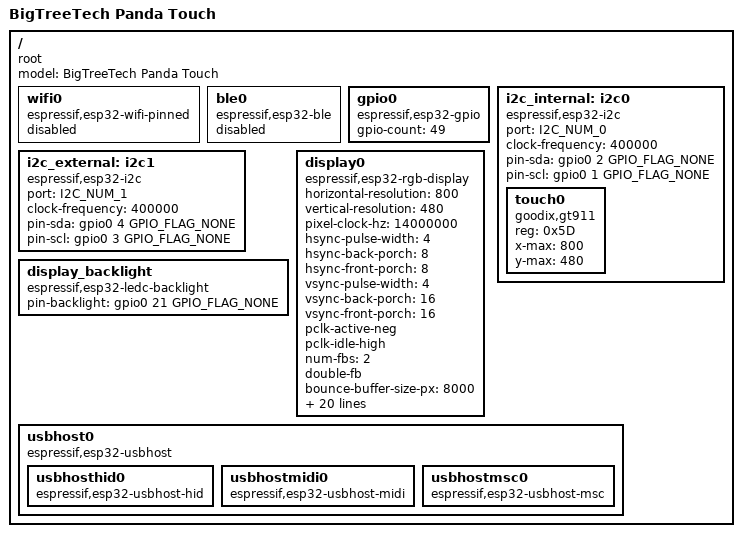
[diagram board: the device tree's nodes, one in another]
/dts-v1/;

#include <tactility/bindings/root.h>
#include <tactility/bindings/esp32_ble.h>
#include <tactility/bindings/esp32_wifi_pinned.h>
#include <tactility/bindings/esp32_gpio.h>
#include <tactility/bindings/esp32_i2c.h>
#include <tactility/bindings/esp32_usbhost.h>
#include <tactility/bindings/esp32_ledc_backlight.h>
#include <bindings/rgb_display.h>
#include <bindings/gt911.h>

// Reference: https://github.com/bigtreetech/PandaTouch_PlatformIO/blob/master/docs/PINOUT.md
/ {
	compatible = "root";
	model = "BigTreeTech Panda Touch";

	wifi0 {
		compatible = "espressif,esp32-wifi-pinned";
		status = "disabled";
	};

	ble0 {
		compatible = "espressif,esp32-ble";
		status = "disabled";
	};

	gpio0 {
		compatible = "espressif,esp32-gpio";
		gpio-count = <49>;
	};

	i2c_internal: i2c0 {
		compatible = "espressif,esp32-i2c";
		port = <I2C_NUM_0>;
		clock-frequency = <400000>;
		pin-sda = <&gpio0 2 GPIO_FLAG_NONE>;
		pin-scl = <&gpio0 1 GPIO_FLAG_NONE>;

		touch0 {
			// Reset pin 41 and interrupt pin 40 exist on the board but are not wired up here
			// (unverified - left disconnected like the original deprecated-HAL config).
			compatible = "goodix,gt911";
			reg = <0x5D>;
			x-max = <800>;
			y-max = <480>;
		};
	};

	i2c_external: i2c1 {
		compatible = "espressif,esp32-i2c";
		port = <I2C_NUM_1>;
		clock-frequency = <400000>;
		pin-sda = <&gpio0 4 GPIO_FLAG_NONE>;
		pin-scl = <&gpio0 3 GPIO_FLAG_NONE>;
	};

	display_backlight {
		compatible = "espressif,esp32-ledc-backlight";
		pin-backlight = <&gpio0 21 GPIO_FLAG_NONE>;
	};

	display0 {
		compatible = "espressif,esp32-rgb-display";
		horizontal-resolution = <800>;
		vertical-resolution = <480>;
		pixel-clock-hz = <14000000>;
		hsync-pulse-width = <4>;
		hsync-back-porch = <8>;
		hsync-front-porch = <8>;
		vsync-pulse-width = <4>;
		vsync-back-porch = <16>;
		vsync-front-porch = <16>;
		pclk-active-neg;
		pclk-idle-high;
		num-fbs = <2>;
		double-fb;
		bounce-buffer-size-px = <8000>;
		pin-de = <&gpio0 38 GPIO_FLAG_NONE>;
		pin-pclk = <&gpio0 5 GPIO_FLAG_NONE>;
		pin-reset = <&gpio0 46 GPIO_FLAG_NONE>;
		pin-data0 = <&gpio0 17 GPIO_FLAG_NONE>; // B
		pin-data1 = <&gpio0 18 GPIO_FLAG_NONE>; // B
		pin-data2 = <&gpio0 48 GPIO_FLAG_NONE>; // B
		pin-data3 = <&gpio0 47 GPIO_FLAG_NONE>; // B
		pin-data4 = <&gpio0 39 GPIO_FLAG_NONE>; // B
		pin-data5 = <&gpio0 11 GPIO_FLAG_NONE>; // G
		pin-data6 = <&gpio0 12 GPIO_FLAG_NONE>; // G
		pin-data7 = <&gpio0 13 GPIO_FLAG_NONE>; // G
		pin-data8 = <&gpio0 14 GPIO_FLAG_NONE>; // G
		pin-data9 = <&gpio0 15 GPIO_FLAG_NONE>; // G
		pin-data10 = <&gpio0 16 GPIO_FLAG_NONE>; // G
		pin-data11 = <&gpio0 6 GPIO_FLAG_NONE>; // R
		pin-data12 = <&gpio0 7 GPIO_FLAG_NONE>; // R
		pin-data13 = <&gpio0 8 GPIO_FLAG_NONE>; // R
		pin-data14 = <&gpio0 9 GPIO_FLAG_NONE>; // R
		pin-data15 = <&gpio0 10 GPIO_FLAG_NONE>; // R
		backlight = <&display_backlight>;
	};

	usbhost0 {
		compatible = "espressif,esp32-usbhost";

		usbhosthid0 {
			compatible = "espressif,esp32-usbhost-hid";
			//status = "disabled";
		};

		usbhostmidi0 {
			compatible = "espressif,esp32-usbhost-midi";
			//status = "disabled";
		};

		usbhostmsc0 {
			compatible = "espressif,esp32-usbhost-msc";
			//status = "disabled";
		};
	};
};
